# XMC4300 register map
Vendor: Infineon; File version: 1.0.4 (Reference Manual v1.0)
CPU: CM4 r2p0, little endian, MPU, FPU, 6 interrupt priority bits
Registers are 32-bit, read-write, reset 0x0 unless marked. A register's access mark holds for its fields unless they carry their own. Offsets are from the block's base; [hi:lo] are bit positions; 'fields as' and 'values as' point back to an identical list.

## SCU_HIBERNATE — System Control Unit
Base 0x50004300
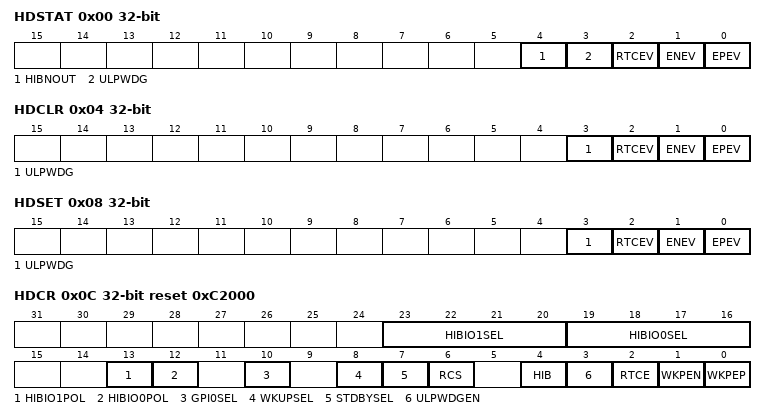
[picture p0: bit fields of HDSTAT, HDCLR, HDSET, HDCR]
0x00 HDSTAT ro — Hibernate Domain Status Register
  [4] HIBNOUT — Hibernate Control Status
    0=Const_0 (Hibernate not driven active to pads); 1=Const_1 (Hibernate driven active to pads)
  [3] ULPWDG — ULP WDG Alarm Status
    0=Const_0 (Watchdog alarm did not occur); 1=Const_1 (Watchdog alarm occurred)
  [2] RTCEV — RTC Event
    0=Const_0 (Wake-up on RTC event inactive); 1=Const_1 (Wake-up on RTC event active)
  [1] ENEV — Wake-up Pin Event Negative Edge
    0=Const_0 (Wake-up on negative edge pin event inactive); 1=Const_1 (Wake-up on negative edge pin event active)
  [0] EPEV — Wake-up Pin Event Positive Edge
    0=Const_0 (Wake-up on positive edge pin event inactive); 1=Const_1 (Wake-up on positive edge pin event active)
0x04 HDCLR wo — Hibernate Domain Status Clear Register
  [3] ULPWDG — ULP WDG Alarm Clear
    0=Const_0 (No effect); 1=Const_1 (Clear watchdog alarm)
  [2] RTCEV — RTC Event Clear
    0=Const_0 (No effect); 1=Const_1 (Clear wake-up event)
  [1] ENEV — Wake-up Pin Event Negative Edge Clear
    0=Const_0 (No effect); 1=Const_1 (Clear wake-up event)
  [0] EPEV — Wake-up Pin Event Positive Edge Clear
    0=Const_0 (No effect); 1=Const_1 (Clear wake-up event)
0x08 HDSET wo — Hibernate Domain Status Set Register
  [3] ULPWDG — ULP WDG Alarm Set
    0=Const_0 (No effect); 1=Const_1 (Set watchdog alarm)
  [2] RTCEV — RTC Event Set
    0=Const_0 (No effect); 1=Const_1 (Set wake-up event)
  [1] ENEV — Wake-up Pin Event Negative Edge Set
    0=Const_0 (No effect); 1=Const_1 (Set wake-up event)
  [0] EPEV — Wake-up Pin Event Positive Edge Set
    0=Const_0 (No effect); 1=Const_1 (Set wake-up event)
0x0C HDCR reset 0xC2000 — Hibernate Domain Control Register
  [23:20] HIBIO1SEL — HIB_IO_1 Pin I/O Control (Default WKUP)
    0=Const_0000 (Direct input, No input pull device connected); 1=Const_0001 (Direct input, Input pull-down device connected); 2=Const_0010 (Direct input, Input pull-up device connected); 8=Const_1000 (Push-pull HIB Control output); 9=Const_1001 (Push-pull WDT service output); 10=Const_1010 (Push-pull GPIO output); 12=Const_1100 (Open-drain HIB Control output); 13=Const_1101 (Open-drain WDT service output); 14=Const_1110 (Open-drain GPIO output); 15=Const_1111 (#1111)
  [19:16] HIBIO0SEL — HIB_IO_0 Pin I/O Control (default HIBOUT)
    values as HIBIO1SEL
  [13] HIBIO1POL — HIBIO1 Polarity Set
    0=Const_0 (Direct value); 1=Const_1 (Inverted value)
  [12] HIBIO0POL — HIBIO0 Polarity Set
    0=Const_0 (Direct value); 1=Const_1 (Inverted value)
  [10] GPI0SEL — General Purpose Input 0 Selection
    0=Const_0 (#0); 1=Const_1 (HIB_IO_0 pin selected)
  [8] WKUPSEL — Wake-Up from Hibernate Trigger Input Selection
    0=Const_0 (HIB_IO_1 pin selected); 1=Const_1 (HIB_IO_0 pin selected)
  [7] STDBYSEL — fSTDBY Clock Selection
    0=Const_0 (fOSI selected); 1=Const_1 (fULP selected)
  [6] RCS — fRTC Clock Selection
    0=Const_0 (fOSI selected); 1=Const_1 (fULP selected)
  [4] HIB — Hibernate Request Value Set
    0=Const_0 (External hibernate request inactive); 1=Const_1 (External hibernate request active)
  [3] ULPWDGEN — ULP WDG Alarm Enable
    0=Const_0 (Wake-up event disabled); 1=Const_1 (Wake-up event enabled)
  [2] RTCE — Wake-up on RTC Event Enable
    values as ULPWDGEN
  [1] WKPEN — Wake-up on Pin Event Negative Edge Enable
    values as ULPWDGEN
  [0] WKPEP — Wake-Up on Pin Event Positive Edge Enable
    values as ULPWDGEN
0x14 OSCSICTRL reset 0x1 — fOSI Control Register
  [0] PWD — Turn OFF the fOSI Clock Source
    0=Const_0 (Enabled); 1=Const_1 (Disabled)
0x18 OSCULSTAT ro — OSC_ULP Status Register
  [0] X1D — XTAL1 Data Value
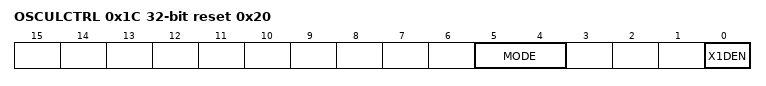
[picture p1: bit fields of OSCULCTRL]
0x1C OSCULCTRL reset 0x20 — OSC_ULP Control Register
  [5:4] MODE — Oscillator Mode
    0=Const_00 (Oscillator is enabled, in operation); 1=Const_01 (Oscillator is enabled, in bypass mode); 2=Const_10 (Oscillator in power down); 3=Const_11 (Oscillator in power down, can be used as GPI)
  [0] X1DEN — XTAL1 Data General Purpose Input Enable
    0=Const_0 (Data input inactivated, power down); 1=Const_1 (Data input active)
